# R7FA0E209 register map
Vendor: Renesas Electronics Corporation; Series: RA0; File version: 1.00.00
CPU: CM23 r1p0, little endian, no MPU, no FPU, VTOR, 2 interrupt priority bits, 64 interrupts
Registers are 16-bit, read-write, reset 0x0 unless marked. A register's access mark holds for its fields unless they carry their own. Offsets are from the block's base; [hi:lo] are bit positions; {n}, {i} and the like mark numbered series; 'fields as' and 'values as' point back to an identical list.

## PFS_A — Pmn Pin Function Select
Base 0x400A0200
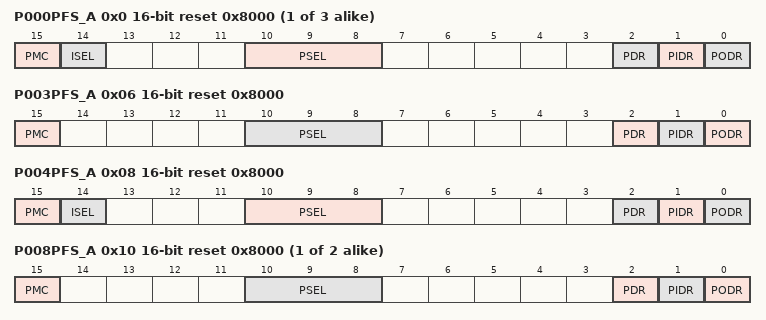
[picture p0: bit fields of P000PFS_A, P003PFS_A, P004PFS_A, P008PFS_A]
{0x0+2i} P00{i}PFS_A (i=0..2) reset 0x8000 (reset mask 0xFFFD) — Port 00{i} Pin Function Select Register
  [15] PMC — Pin Mode Control
    0=Digital I/O; 1=Analog input function. Input to the input buffer is disable
  [14] ISEL — IRQ Input Enable
    0=Not used as an IRQn input pin; 1=Used as an IRQn input pin
  [10:8] PSEL — Peripheral Select
  [2] PDR — P0%s Direction
    0=Input (functions as an input pin); 1=Output (functions as an output pin)
  [1] PIDR ro — P0%s State
    0=Low level; 1=High level
  [0] PODR — P0%s Output Data
    0=Low output; 1=High output
0x06 P003PFS_A reset 0x8000 (reset mask 0xFFFD) — Port 003 Pin Function Select Register
  [15] PMC — Pin Mode Control
    values as P000PFS_A.PMC
  [10:8] PSEL — Peripheral Select
  [2] PDR — P0n Direction
    values as P000PFS_A.PDR
  [1] PIDR ro — P0n State
    0=Low level; 1=High level
  [0] PODR — P0n Output Data
    0=Low output; 1=High output
0x08 P004PFS_A reset 0x8000 (reset mask 0xFFFD) — Port 004 Pin Function Select Register
  [15] PMC — Pin Mode Control
    values as P000PFS_A.PMC
  [14] ISEL — IRQ Input Enable
    0=Not used as an IRQn input pin; 1=Used as an IRQn input pin
  [10:8] PSEL — Peripheral Select
  [2] PDR — P0n Direction
    values as P000PFS_A.PDR
  [1] PIDR ro — P0n State
    0=Low level; 1=High level
  [0] PODR — P0n Output Data
    0=Low output; 1=High output
{0x0+2i} P00{i}PFS_A (i=8..9) reset 0x8000 (reset mask 0xFFFD) — Port 00{i} Pin Function Select Register
  [15] PMC — Pin mode control
    values as P000PFS_A.PMC
  [10:8] PSEL — These bits select the peripheral function. For individual pin functions, see the associated tables in this chapter.
  [2] PDR
    values as P000PFS_A.PDR
  [1] PIDR ro — Pmn State
    0=Low level; 1=High level
  [0] PODR — Port Output Data
    0=Low output; 1=High output
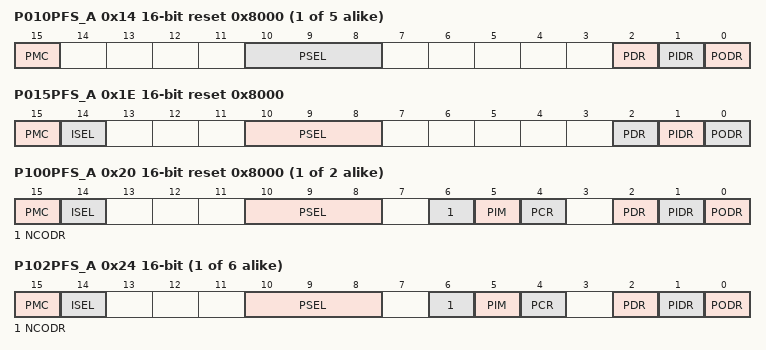
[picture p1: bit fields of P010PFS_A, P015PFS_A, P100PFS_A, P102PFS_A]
{0x0+2i} P0{i}PFS_A (i=10..14) reset 0x8000 (reset mask 0xFFFD) — Port 0{i} Pin Function Select Register
  fields as P008PFS_A
0x1E P015PFS_A reset 0x8000 (reset mask 0xFFFD) — Port 015 Pin Function Select Register
  [15] PMC — Pin mode control
    values as P000PFS_A.PMC
  [14] ISEL — IRQ Input Enable
    0=Not used as an IRQn input pin; 1=Used as an IRQn input pin
  [10:8] PSEL — These bits select the peripheral function. For individual pin functions, see the associated tables in this chapter.
  [2] PDR
    values as P000PFS_A.PDR
  [1] PIDR ro — Pmn State
    0=Low output; 1=High output
  [0] PODR — Port Output Data
    0=Low output; 1=High output
{0x20+2i} P10{i}PFS_A (i=0..1) reset 0x8000 (reset mask 0xFFFD) — Port 10{i} Pin Function Select Register
  [15] PMC — Pin mode control
    values as P000PFS_A.PMC
  [14] ISEL — IRQ Input Enable
    0=Not used as an IRQn input pin; 1=Used as an IRQn input pin
  [10:8] PSEL — These bits select the peripheral function. For individual pin functions, see the associated tables in this chapter.
  [6] NCODR
    values as P000PFS_A.PDR
  [5] PIM
    values as P000PFS_A.PDR
  [4] PCR
    0=Disable input pull-up; 1=Enable input pull-up
  [2] PDR
    values as P000PFS_A.PDR
  [1] PIDR ro — Pmn State
    0=Low output; 1=High output
  [0] PODR — Port Output Data
    0=Low output; 1=High output
{0x20+2i} P10{i}PFS_A (i=2..7) (reset mask 0xFFFD) — Port 10{i} Pin Function Select Register
  fields as P100PFS_A
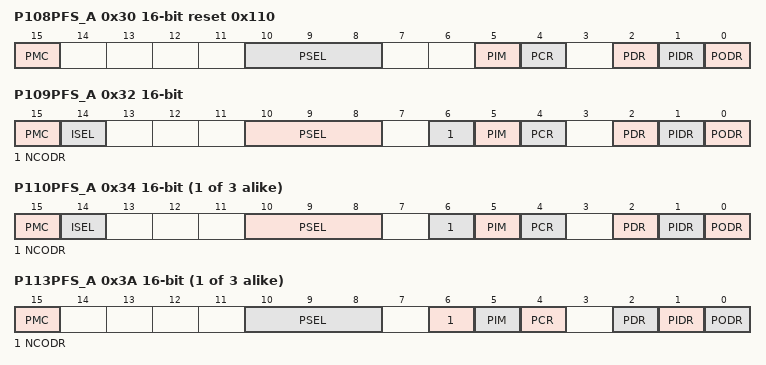
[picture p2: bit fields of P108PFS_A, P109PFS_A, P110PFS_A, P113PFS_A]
0x30 P108PFS_A reset 0x110 (reset mask 0xFFFD) — Port 108 Pin Function Select Register
  [15] PMC — Pin mode control
    values as P000PFS_A.PMC
  [10:8] PSEL — These bits select the peripheral function. For individual pin functions, see the associated tables in this chapter.
  [5] PIM
    values as P000PFS_A.PDR
  [4] PCR
    0=Disable input pull-up; 1=Enable input pull-up
  [2] PDR
    values as P000PFS_A.PDR
  [1] PIDR ro — Pmn State
    0=Low output; 1=High output
  [0] PODR — Port Output Data
    0=Low output; 1=High output
0x32 P109PFS_A (reset mask 0xFFFD) — Port 109 Pin Function Select Register
  fields as P100PFS_A
{0x20+2i} P1{i}PFS_A (i=10..12) (reset mask 0xFFFD) — Port 1{i} Pin Function Select Register
  fields as P100PFS_A
{0x20+2i} P1{i}PFS_A (i=13..15) (reset mask 0xFFFD) — Port 1{i} Pin Function Select Register
  [15] PMC — Pin mode control
    values as P000PFS_A.PMC
  [10:8] PSEL — These bits select the peripheral function. For individual pin functions, see the associated tables in this chapter.
  [6] NCODR
    values as P000PFS_A.PDR
  [5] PIM
    values as P000PFS_A.PDR
  [4] PCR
    0=Disable input pull-up; 1=Enable input pull-up
  [2] PDR
    values as P000PFS_A.PDR
  [1] PIDR ro — Pmn State
    0=Low output; 1=High output
  [0] PODR — Port Output Data
    0=Low output; 1=High output
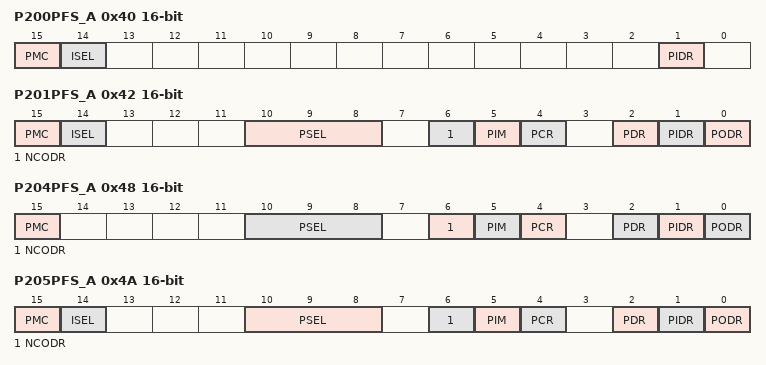
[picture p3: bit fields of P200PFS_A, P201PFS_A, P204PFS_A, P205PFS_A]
0x40 P200PFS_A (reset mask 0xFFFD) — Port 200 Pin Function Select Register
  [15] PMC — Pin mode control
    values as P000PFS_A.PMC
  [14] ISEL — IRQ Input Enable
    0=Not used as an IRQn input pin; 1=Used as an IRQn input pin
  [1] PIDR ro — Pmn State
    0=Low output; 1=High output
0x42 P201PFS_A (reset mask 0xFFFD) — Port 201 Pin Function Select Register
  fields as P100PFS_A
0x48 P204PFS_A (reset mask 0xFFFD) — Port 204 Pin Function Select Register
  fields as P113PFS_A
0x4A P205PFS_A (reset mask 0xFFFD) — Port 205 Pin Function Select Register
  fields as P100PFS_A
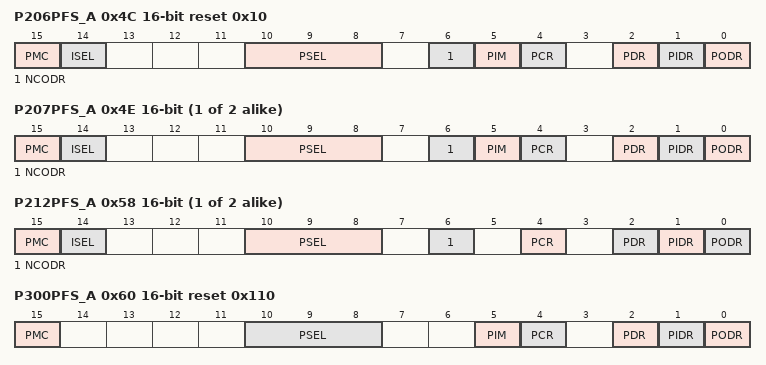
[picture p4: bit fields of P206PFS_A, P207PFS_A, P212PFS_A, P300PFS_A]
0x4C P206PFS_A reset 0x10 (reset mask 0xFFFD) — Port 206 Pin Function Select Register
  fields as P100PFS_A
{0x40+2i} P20{i}PFS_A (i=7..8) (reset mask 0xFFFD) — Port 20{i} Pin Function Select Register
  fields as P100PFS_A
{0x40+2i} P2{i}PFS_A (i=12..13) (reset mask 0xFFFD) — Port 2{i} Pin Function Select Register
  [15] PMC — Pin mode control
    values as P000PFS_A.PMC
  [14] ISEL — IRQ Input Enable
    0=Not used as an IRQn input pin; 1=Used as an IRQn input pin
  [10:8] PSEL — These bits select the peripheral function. For individual pin functions, see the associated tables in this chapter.
  [6] NCODR
    values as P000PFS_A.PDR
  [4] PCR
    0=Disable input pull-up; 1=Enable input pull-up; 0=Input (functions as an input pin)
  [2] PDR
    values as P000PFS_A.PDR
  [1] PIDR ro — Pmn State
    0=Low output; 1=High output
  [0] PODR — Port Output Data
    0=Low output; 1=High output
{0x40+2i} P2{i}PFS_A (i=14..15) (reset mask 0xFFFD) — Port 2{i} Pin Function Select Register
  [1] PIDR ro — Pmn State
    0=Low output; 1=High output; 0=Input (functions as an input pin)
0x60 P300PFS_A reset 0x110 (reset mask 0xFFFD) — Port 300 Pin Function Select Register
  fields as P108PFS_A
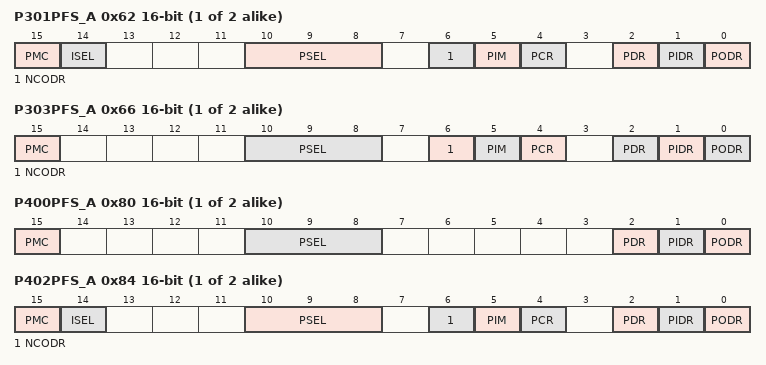
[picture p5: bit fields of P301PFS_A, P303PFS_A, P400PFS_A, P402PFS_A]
{0x60+2i} P30{i}PFS_A (i=1..2) (reset mask 0xFFFD) — Port 30{i} Pin Function Select Register
  fields as P100PFS_A
{0x60+2i} P30{i}PFS_A (i=3..4) (reset mask 0xFFFD) — Port 30{i} Pin Function Select Register
  fields as P113PFS_A
{0x80+2i} P40{i}PFS_A (i=0..1) (reset mask 0xFFFD) — Port 40{i} Pin Function Select Register
  [15] PMC — Pin Mode Control
    values as P000PFS_A.PMC
  [10:8] PSEL — Peripheral Select
  [2] PDR — P4%s Direction
    values as P000PFS_A.PDR
  [1] PIDR ro — P4%s State
    0=Low level; 1=High level
  [0] PODR — P4%s Output Data
    0=Low output; 1=High output
{0x80+2i} P40{i}PFS_A (i=2..3) (reset mask 0xFFFD) — Port 40{i} Pin Function Select Register
  fields as P100PFS_A
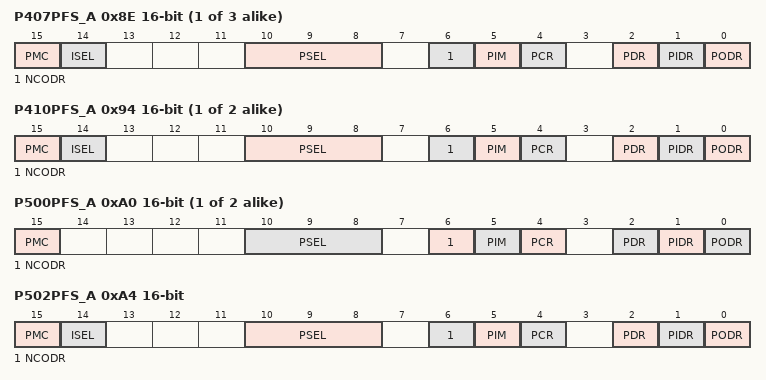
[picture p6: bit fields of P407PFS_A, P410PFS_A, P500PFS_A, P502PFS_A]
{0x80+2i} P40{i}PFS_A (i=7..9) (reset mask 0xFFFD) — Port 40{i} Pin Function Select Register
  fields as P100PFS_A
{0x80+2i} P4{i}PFS_A (i=10..11) (reset mask 0xFFFD) — Port 4{i} Pin Function Select Register
  fields as P100PFS_A
{0xA0+2i} P50{i}PFS_A (i=0..1) (reset mask 0xFFFD) — Port 50{i} Pin Function Select Register
  fields as P113PFS_A
0xA4 P502PFS_A (reset mask 0xFFFD) — Port 502 Pin Function Select Register
  fields as P100PFS_A
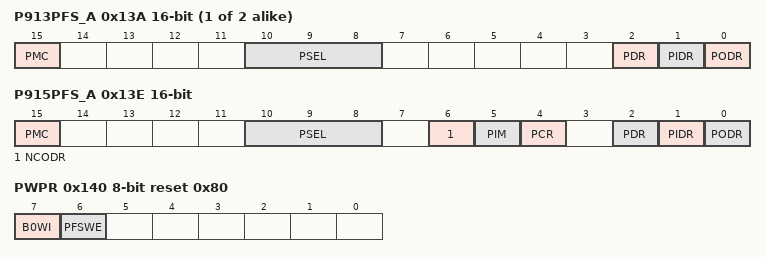
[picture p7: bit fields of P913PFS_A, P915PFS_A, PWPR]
{0x120+2i} P9{i}PFS_A (i=13..14) (reset mask 0xFFFD) — Port 9{i} Pin Function Select Register
  [15] PMC — Pin Mode Control
    values as P000PFS_A.PMC
  [10:8] PSEL — Peripheral Select
  [2] PDR — P9%s Direction
    values as P000PFS_A.PDR
  [1] PIDR ro — P9%s State
    0=Low level; 1=High level
  [0] PODR — P9%s Output Data
    0=Low output; 1=High output
0x13E P915PFS_A (reset mask 0xFFFD) — Port 915 Pin Function Select Register
  fields as P113PFS_A
0x140 PWPR 8-bit reset 0x80 — Write-Protect Register
  [7] B0WI — PFSWE Bit Write Disable
    0=Writing to the PFSWE bit is enabled; 1=Writing to the PFSWE bit is disabled
  [6] PFSWE — PmnPFS_A Register Write Enable
    0=Writing to the PmnPFS_A register is disabled; 1=Writing to the PmnPFS_A register is enabled
